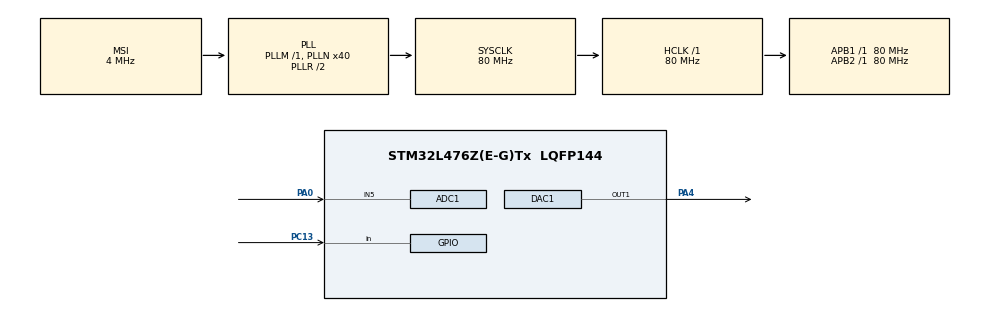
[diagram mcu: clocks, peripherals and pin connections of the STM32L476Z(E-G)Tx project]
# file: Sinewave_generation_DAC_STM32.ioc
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ADC1.Channel-0\#ChannelRegularConversion=ADC_CHANNEL_5
ADC1.ClockPrescaler=ADC_CLOCK_ASYNC_DIV1
ADC1.ContinuousConvMode=DISABLE
ADC1.NbrOfConversion=1
ADC1.NbrOfConversionFlag=1
ADC1.OffsetNumber-0\#ChannelRegularConversion=ADC_OFFSET_NONE
ADC1.Rank-0\#ChannelRegularConversion=1
ADC1.SamplingTime-0\#ChannelRegularConversion=ADC_SAMPLETIME_2CYCLES_5
ADC1.master=1
DAC1.DAC_Trigger-DAC_OUT1_ExtAndInt=DAC_TRIGGER_T2_TRGO
Dma.DAC_CH1.0.Direction=DMA_MEMORY_TO_PERIPH
Dma.DAC_CH1.0.Instance=DMA1_Channel3
Dma.DAC_CH1.0.MemDataAlignment=DMA_MDATAALIGN_WORD
Dma.DAC_CH1.0.MemInc=DMA_MINC_ENABLE
Dma.DAC_CH1.0.Mode=DMA_CIRCULAR
Dma.DAC_CH1.0.PeriphDataAlignment=DMA_PDATAALIGN_WORD
Dma.DAC_CH1.0.PeriphInc=DMA_PINC_DISABLE
Dma.DAC_CH1.0.Priority=DMA_PRIORITY_LOW
Dma.Request0=DAC_CH1
Mcu.Family=STM32L4
Mcu.Name=STM32L476Z(E-G)Tx
Mcu.Package=LQFP144
NVIC.DMA1_Channel3_IRQn=true\:0\:0\:false\:false\:true\:false\:true\:true
NVIC.PriorityGroup=NVIC_PRIORITYGROUP_4
NVIC.TIM2_IRQn=true\:0\:0\:false\:false\:true\:true\:true\:true
PA0.Signal=ADCx_IN5
PA13\ (JTMS-SWDIO).Mode=Serial_Wire
PA13\ (JTMS-SWDIO).Signal=SYS_JTMS-SWDIO
PA14\ (JTCK-SWCLK).Mode=Serial_Wire
PA14\ (JTCK-SWCLK).Signal=SYS_JTCK-SWCLK
PA4.Signal=COMP_DAC11_group
PC13.GPIO_PuPd=GPIO_PULLUP
PC13.Signal=GPIO_Input
PC14-OSC32_IN\ (PC14).Mode=LSE-External-Oscillator
PC14-OSC32_IN\ (PC14).Signal=RCC_OSC32_IN
PC15-OSC32_OUT\ (PC15).Mode=LSE-External-Oscillator
PC15-OSC32_OUT\ (PC15).Signal=RCC_OSC32_OUT
PH0-OSC_IN\ (PH0).Mode=HSE-External-Oscillator
PH0-OSC_IN\ (PH0).Signal=RCC_OSC_IN
PH1-OSC_OUT\ (PH1).Mode=HSE-External-Oscillator
PH1-OSC_OUT\ (PH1).Signal=RCC_OSC_OUT
ProjectManager.HeapSize=0x200
ProjectManager.StackSize=0x400
ProjectManager.TargetToolchain=STM32CubeIDE
RCC.ADCFreq_Value=32000000
RCC.AHBFreq_Value=80000000
RCC.APB1Freq_Value=80000000
RCC.APB1TimFreq_Value=80000000
RCC.APB2Freq_Value=80000000
RCC.APB2TimFreq_Value=80000000
RCC.CortexFreq_Value=80000000
RCC.HCLKFreq_Value=80000000
RCC.HSE_VALUE=8000000
RCC.HSI_VALUE=16000000
RCC.MSI_VALUE=4000000
RCC.PLLN=40
RCC.PLLSAI1N=16
RCC.SYSCLKFreq_VALUE=80000000
RCC.SYSCLKSource=RCC_SYSCLKSOURCE_PLLCLK
RCC.USBFreq_Value=32000000
RCC.VCOOutputFreq_Value=160000000
SH.ADCx_IN5.0=ADC1_IN5,IN5-Single-Ended
SH.COMP_DAC11_group.0=DAC1_OUT1,DAC_OUT1_ExtAndInt
TIM2.Period=100-1
TIM2.Prescaler=80-1
TIM2.TIM_MasterOutputTrigger=TIM_TRGO_UPDATE
VP_TIM2_VS_ClockSourceINT.Mode=Internal
board=custom

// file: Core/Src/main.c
/* USER CODE BEGIN Header */
/**
  ******************************************************************************
  * @file           : main.c
  * @brief          : Main program body
  ******************************************************************************
  * @attention
  *
  * Copyright (c) 2024 STMicroelectronics.
  * All rights reserved.
  *
  * This software is licensed under terms that can be found in the LICENSE file
  * in the root directory of this software component.
  * If no LICENSE file comes with this software, it is provided AS-IS.
  *
  ******************************************************************************
  */
/* USER CODE END Header */
#include "main.h"

/* USER CODE BEGIN Includes */
#include "math.h"
/* USER CODE END Includes */

/* USER CODE BEGIN PD */
#define MAX_FREQUENCY 1000 // Maximum frequency in Hz
#define MIN_FREQUENCY 100  // Minimum frequency in Hz
#define ADC_RESOLUTION 4096 // 12-bit ADC
#define DAC_RESOLUTION 4096 // 12-bit DAC
#define PI             3.1415926
/* USER CODE END PD */

ADC_HandleTypeDef hadc1;

DAC_HandleTypeDef hdac1;
DMA_HandleTypeDef hdma_dac_ch1;

TIM_HandleTypeDef htim2;

void SystemClock_Config(void);
static void MX_GPIO_Init(void);
static void MX_DMA_Init(void);
static void MX_ADC1_Init(void);
static void MX_DAC1_Init(void);
static void MX_TIM2_Init(void);

/* USER CODE BEGIN 0 */
uint16_t square_val[100]; // Square wave lookup table
uint32_t sine_val[100]; // Sine wave lookup table
uint32_t adc_value = 0;      // ADC value (potentiometer position)
uint8_t waveform_flag = 0;    // 0 = Sine wave, 1 = Square wave
uint8_t button_pressed  = 0;     // Button state for toggling
uint32_t frequency = 100;    // Initial frequency

void get_squareval() // Generating Square wave
{
    for (int i = 0; i < 100; i++)
    {
        if (i < 50) // First half of the cycle
        {
            square_val[i] = 4095; // High level (12-bit DAC maximum)
        }
        else // Second half of the cycle
        {
            square_val[i] = 0; // Low level
        }
    }
}

void Generate_SineWave()                                // Generating Sine wave
{
	for (int i = 0; i < 100; i++) {
       sine_val[i] = (uint16_t)((sin(2 * PI * i / 100) + 1) * (4096 / 2));
   }
}

uint8_t Read_Button(void)
{
	static uint8_t prev_state = 1; // Button State (not pressed)
	uint8_t current_state = HAL_GPIO_ReadPin(GPIOC, GPIO_PIN_13);

	if (prev_state == 1 && current_state == 0) {       // Detect falling edge
	        HAL_Delay(150);                           // Debounce delay
	        if (HAL_GPIO_ReadPin(GPIOC, GPIO_PIN_13) == 0) {
	            prev_state = 0;
	            return 1;                              // Button pressed
	        }
	    } else if (current_state == 1) {
	        prev_state = 1;                           // Button released
	    }
	    return 0;                                     // No button press detected

}

void Update_Timer_Frequency(uint32_t frequency)
{
	 uint32_t timer_clock = HAL_RCC_GetPCLK1Freq(); // Timer clock frequency
	 uint32_t prescaler = (timer_clock / 1000000) - 1; // Prescaler for 1 MHz base clock
	 uint32_t period = (1000000 / (frequency * 100)) - 1; // Calculate ARR value

	 // Update timer configuration
	     htim2.Init.Prescaler = prescaler;
	     htim2.Init.Period = period;
	     HAL_TIM_Base_Init(&htim2);

}

//void HAL_TIM_PeriodElapsedCallback(TIM_HandleTypeDef *htim) {
//    static uint8_t sample_index = 0;
//
//    if (htim->Instance == TIM2) {
//    	//if (waveform_flag == 0) {
//        // Output the current sine wave sample
//        HAL_DAC_SetValue(&hdac1, DAC_CHANNEL_1, DAC_ALIGN_12B_R, sine_val[sample_index]);      // Output Sine wave
//    	//} else {
//    	//HAL_DAC_SetValue(&hdac1, DAC_CHANNEL_1, DAC_ALIGN_12B_R, square_val[sample_index]);    // Output square wave
//
//        sample_index = (sample_index + 1) % 100; // Increment sample index
//    }
//}
//void Toggle_Waveform(void)
//{
//    waveform_flag = !waveform_flag; // Toggle between 0 and 1
//}
//void HAL_GPIO_EXTI_Callback(uint16_t GPIO_Pin) {
//    if (GPIO_Pin == GPIO_PIN_13) {
//        button_pressed = 1; // Set button press flag
//    }
//}
/* USER CODE END 0 */

int main(void)
{

  /* MCU Configuration--------------------------------------------------------*/

  /* Reset of all peripherals, Initializes the Flash interface and the Systick. */
  HAL_Init();

  /* Configure the system clock */
  SystemClock_Config();

  /* Initialize all configured peripherals */
  MX_GPIO_Init();
  MX_DMA_Init();
  MX_ADC1_Init();
  MX_DAC1_Init();
  MX_TIM2_Init();
  /* USER CODE BEGIN 2 */

//  get_squareval();
 // Generate_SineWave();  // Create sine wave lookup table
 // get_squareval();      // Create square wave lookup table

  HAL_TIM_Base_Start(&htim2);
  HAL_DAC_Start(&hdac1, DAC_CHANNEL_1);
  if (Read_Button())
//  {
// 	              waveform_flag = !waveform_flag; // Toggle waveform flag
//  }
      if (waveform_flag == 1){

 	 Generate_SineWave();
 	 HAL_DAC_Start_DMA(&hdac1, DAC_CHANNEL_1, sine_val, 100, DAC_ALIGN_12B_R);
      }else if (waveform_flag == 0){
     	// HAL_DAC_Start_DMA(&hdac1, DAC_CHANNEL_1, square_val, 100, DAC_ALIGN_12B_R);
 	 get_squareval();
      }

  //HAL_DAC_Start_DMA(&hdac1, DAC_CHANNEL_1, sine_val, 100, DAC_ALIGN_12B_R);

  //get_squareval(); // Generate square wave data
  // For sine wave, call "Generate_SineWave();" to Generate sine wave data
     //HAL_DAC_Start(&hdac1, DAC_CHANNEL_1);
    // HAL_TIM_Base_Start_IT(&htim2);
  /* USER CODE END 2 */

  /* Infinite loop */
  /* USER CODE BEGIN WHILE */
  while (1)
  {
	  HAL_ADC_Start(&hadc1);  // Reading ADC value
	  	  if(HAL_ADC_PollForConversion(&hadc1, 1000) == HAL_OK)
	  		{
	  		  adc_value = HAL_ADC_GetValue(&hadc1);
	  	  }
	  	  HAL_ADC_Stop(&hadc1);

	  	  // Map ADC value to frequency range
	  	  frequency = MIN_FREQUENCY + ((adc_value * (MAX_FREQUENCY - MIN_FREQUENCY)) / ADC_RESOLUTION);

	  	  // Update timer frequency
	  	  Update_Timer_Frequency(frequency);

	  	 //

//	  readValue = HAL_ADC_GetValue(&hadc1);
//	  HAL_Delay(100);

//	  var = value*(0xfff+1)/3.3;
//	  HAL_DAC_SetValue(&hdac1, DAC_CHANNEL_1, DAC_ALIGN_12B_R, var);
//	  value = value + 0.5;
//
//	  HAL_Delay(2000);
//
//	  if(value>3) value = 0.2;

    /* USER CODE END WHILE */

  }
}

void SystemClock_Config(void)
{
  RCC_OscInitTypeDef RCC_OscInitStruct = {0};
  RCC_ClkInitTypeDef RCC_ClkInitStruct = {0};

  /** Configure the main internal regulator output voltage
  */
  if (HAL_PWREx_ControlVoltageScaling(PWR_REGULATOR_VOLTAGE_SCALE1) != HAL_OK)
  {
    Error_Handler();
  }

  /** Configure LSE Drive Capability
  */
  HAL_PWR_EnableBkUpAccess();
  __HAL_RCC_LSEDRIVE_CONFIG(RCC_LSEDRIVE_LOW);

  /** Initializes the RCC Oscillators according to the specified parameters
  * in the RCC_OscInitTypeDef structure.
  */
  RCC_OscInitStruct.OscillatorType = RCC_OSCILLATORTYPE_LSE|RCC_OSCILLATORTYPE_MSI;
  RCC_OscInitStruct.LSEState = RCC_LSE_ON;
  RCC_OscInitStruct.MSIState = RCC_MSI_ON;
  RCC_OscInitStruct.MSICalibrationValue = 0;
  RCC_OscInitStruct.MSIClockRange = RCC_MSIRANGE_6;
  RCC_OscInitStruct.PLL.PLLState = RCC_PLL_ON;
  RCC_OscInitStruct.PLL.PLLSource = RCC_PLLSOURCE_MSI;
  RCC_OscInitStruct.PLL.PLLM = 1;
  RCC_OscInitStruct.PLL.PLLN = 40;
  RCC_OscInitStruct.PLL.PLLP = RCC_PLLP_DIV7;
  RCC_OscInitStruct.PLL.PLLQ = RCC_PLLQ_DIV2;
  RCC_OscInitStruct.PLL.PLLR = RCC_PLLR_DIV2;
  if (HAL_RCC_OscConfig(&RCC_OscInitStruct) != HAL_OK)
  {
    Error_Handler();
  }

  /** Initializes the CPU, AHB and APB buses clocks
  */
  RCC_ClkInitStruct.ClockType = RCC_CLOCKTYPE_HCLK|RCC_CLOCKTYPE_SYSCLK
                              |RCC_CLOCKTYPE_PCLK1|RCC_CLOCKTYPE_PCLK2;
  RCC_ClkInitStruct.SYSCLKSource = RCC_SYSCLKSOURCE_PLLCLK;
  RCC_ClkInitStruct.AHBCLKDivider = RCC_SYSCLK_DIV1;
  RCC_ClkInitStruct.APB1CLKDivider = RCC_HCLK_DIV1;
  RCC_ClkInitStruct.APB2CLKDivider = RCC_HCLK_DIV1;

  if (HAL_RCC_ClockConfig(&RCC_ClkInitStruct, FLASH_LATENCY_4) != HAL_OK)
  {
    Error_Handler();
  }

  /** Enable MSI Auto calibration
  */
  HAL_RCCEx_EnableMSIPLLMode();
}

static void MX_ADC1_Init(void)
{

  ADC_MultiModeTypeDef multimode = {0};
  ADC_ChannelConfTypeDef sConfig = {0};

  /** Common config
  */
  hadc1.Instance = ADC1;
  hadc1.Init.ClockPrescaler = ADC_CLOCK_ASYNC_DIV1;
  hadc1.Init.Resolution = ADC_RESOLUTION_12B;
  hadc1.Init.DataAlign = ADC_DATAALIGN_RIGHT;
  hadc1.Init.ScanConvMode = ADC_SCAN_DISABLE;
  hadc1.Init.EOCSelection = ADC_EOC_SINGLE_CONV;
  hadc1.Init.LowPowerAutoWait = DISABLE;
  hadc1.Init.ContinuousConvMode = DISABLE;
  hadc1.Init.NbrOfConversion = 1;
  hadc1.Init.DiscontinuousConvMode = DISABLE;
  hadc1.Init.ExternalTrigConv = ADC_SOFTWARE_START;
  hadc1.Init.ExternalTrigConvEdge = ADC_EXTERNALTRIGCONVEDGE_NONE;
  hadc1.Init.DMAContinuousRequests = DISABLE;
  hadc1.Init.Overrun = ADC_OVR_DATA_PRESERVED;
  hadc1.Init.OversamplingMode = DISABLE;
  if (HAL_ADC_Init(&hadc1) != HAL_OK)
  {
    Error_Handler();
  }

  /** Configure the ADC multi-mode
  */
  multimode.Mode = ADC_MODE_INDEPENDENT;
  if (HAL_ADCEx_MultiModeConfigChannel(&hadc1, &multimode) != HAL_OK)
  {
    Error_Handler();
  }

  /** Configure Regular Channel
  */
  sConfig.Channel = ADC_CHANNEL_5;
  sConfig.Rank = ADC_REGULAR_RANK_1;
  sConfig.SamplingTime = ADC_SAMPLETIME_2CYCLES_5;
  sConfig.SingleDiff = ADC_SINGLE_ENDED;
  sConfig.OffsetNumber = ADC_OFFSET_NONE;
  sConfig.Offset = 0;
  if (HAL_ADC_ConfigChannel(&hadc1, &sConfig) != HAL_OK)
  {
    Error_Handler();
  }

}

static void MX_DAC1_Init(void)
{

  DAC_ChannelConfTypeDef sConfig = {0};

  /** DAC Initialization
  */
  hdac1.Instance = DAC1;
  if (HAL_DAC_Init(&hdac1) != HAL_OK)
  {
    Error_Handler();
  }

  /** DAC channel OUT1 config
  */
  sConfig.DAC_SampleAndHold = DAC_SAMPLEANDHOLD_DISABLE;
  sConfig.DAC_Trigger = DAC_TRIGGER_T2_TRGO;
  sConfig.DAC_OutputBuffer = DAC_OUTPUTBUFFER_ENABLE;
  sConfig.DAC_ConnectOnChipPeripheral = DAC_CHIPCONNECT_ENABLE;
  sConfig.DAC_UserTrimming = DAC_TRIMMING_FACTORY;
  if (HAL_DAC_ConfigChannel(&hdac1, &sConfig, DAC_CHANNEL_1) != HAL_OK)
  {
    Error_Handler();
  }

}

static void MX_TIM2_Init(void)
{

  TIM_ClockConfigTypeDef sClockSourceConfig = {0};
  TIM_MasterConfigTypeDef sMasterConfig = {0};

  htim2.Instance = TIM2;
  htim2.Init.Prescaler = 80-1;
  htim2.Init.CounterMode = TIM_COUNTERMODE_UP;
  htim2.Init.Period = 100-1;
  htim2.Init.ClockDivision = TIM_CLOCKDIVISION_DIV1;
  htim2.Init.AutoReloadPreload = TIM_AUTORELOAD_PRELOAD_DISABLE;
  if (HAL_TIM_Base_Init(&htim2) != HAL_OK)
  {
    Error_Handler();
  }
  sClockSourceConfig.ClockSource = TIM_CLOCKSOURCE_INTERNAL;
  if (HAL_TIM_ConfigClockSource(&htim2, &sClockSourceConfig) != HAL_OK)
  {
    Error_Handler();
  }
  sMasterConfig.MasterOutputTrigger = TIM_TRGO_UPDATE;
  sMasterConfig.MasterSlaveMode = TIM_MASTERSLAVEMODE_DISABLE;
  if (HAL_TIMEx_MasterConfigSynchronization(&htim2, &sMasterConfig) != HAL_OK)
  {
    Error_Handler();
  }

}

static void MX_DMA_Init(void)
{

  /* DMA controller clock enable */
  __HAL_RCC_DMA1_CLK_ENABLE();

  /* DMA interrupt init */
  /* DMA1_Channel3_IRQn interrupt configuration */
  HAL_NVIC_SetPriority(DMA1_Channel3_IRQn, 0, 0);
  HAL_NVIC_EnableIRQ(DMA1_Channel3_IRQn);

}

static void MX_GPIO_Init(void)
{
  GPIO_InitTypeDef GPIO_InitStruct = {0};

  /* GPIO Ports Clock Enable */
  __HAL_RCC_GPIOC_CLK_ENABLE();
  __HAL_RCC_GPIOH_CLK_ENABLE();
  __HAL_RCC_GPIOA_CLK_ENABLE();

  /*Configure GPIO pin : PC13 */
  GPIO_InitStruct.Pin = GPIO_PIN_13;
  GPIO_InitStruct.Mode = GPIO_MODE_INPUT;
  GPIO_InitStruct.Pull = GPIO_PULLUP;
  HAL_GPIO_Init(GPIOC, &GPIO_InitStruct);

}

void Error_Handler(void)
{
  __disable_irq();
  while (1)
  {
  }
}
